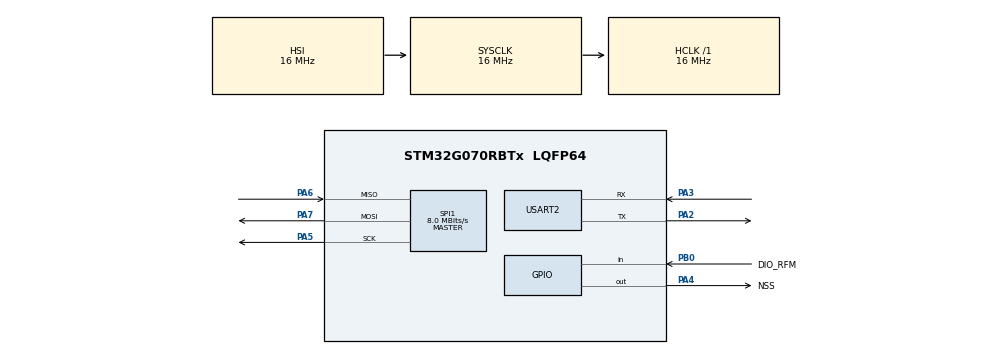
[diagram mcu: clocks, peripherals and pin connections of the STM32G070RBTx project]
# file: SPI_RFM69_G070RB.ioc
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Mcu.Family=STM32G0
Mcu.Name=STM32G070RBTx
Mcu.Package=LQFP64
PA13.GPIO_Label=TMS
PA13.Mode=Serial_Wire
PA13.Signal=SYS_SWDIO
PA14-BOOT0.GPIO_Label=TCK
PA14-BOOT0.Mode=Serial_Wire
PA14-BOOT0.Signal=SYS_SWCLK
PA2.GPIO_PuPd=GPIO_PULLUP
PA2.Mode=Asynchronous
PA2.Signal=USART2_TX
PA3.GPIO_PuPd=GPIO_PULLUP
PA3.Mode=Asynchronous
PA3.Signal=USART2_RX
PA4.GPIO_Label=NSS
PA4.Signal=GPIO_Output
PA5.Mode=Full_Duplex_Master
PA5.Signal=SPI1_SCK
PA6.Mode=Full_Duplex_Master
PA6.Signal=SPI1_MISO
PA7.Mode=Full_Duplex_Master
PA7.Signal=SPI1_MOSI
PB0.GPIO_Label=DIO_RFM
PB0.Signal=GPIO_Input
PC13.Mode=SYS_WakeUp1
PC13.Signal=SYS_WKUP2
PC14-OSC32_IN\ (PC14).Mode=LSE-External-Oscillator
PC14-OSC32_IN\ (PC14).Signal=RCC_OSC32_IN
PC15-OSC32_OUT\ (PC15).Mode=LSE-External-Oscillator
PC15-OSC32_OUT\ (PC15).Signal=RCC_OSC32_OUT
PF0-OSC_IN\ (PF0).GPIO_Label=MCO
PF0-OSC_IN\ (PF0).Mode=HSE-External-Clock-Source
PF0-OSC_IN\ (PF0).Signal=RCC_OSC_IN
ProjectManager.HeapSize=0x200
ProjectManager.StackSize=0x400
ProjectManager.TargetToolchain=Makefile
RCC.AHBFreq_Value=16000000
RCC.CortexFreq_Value=16000000
RCC.EXTERNAL_CLOCK_VALUE=12288000
RCC.HCLKFreq_Value=16000000
RCC.HSE_VALUE=8000000
RCC.HSI_VALUE=16000000
RCC.SYSCLKFreq_VALUE=16000000
RCC.VCOOutputFreq_Value=128000000
SPI1.CalculateBaudRate=8.0 MBits/s
SPI1.DataSize=SPI_DATASIZE_8BIT
SPI1.Direction=SPI_DIRECTION_2LINES
SPI1.Mode=SPI_MODE_MASTER
SPI1.VirtualType=VM_MASTER
USART2.VirtualMode-Asynchronous=VM_ASYNC
USART2.WordLength=WORDLENGTH_8B
board=NUCLEO-G070RB

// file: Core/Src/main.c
/* USER CODE BEGIN Header */
/**
  ******************************************************************************
  * @file           : main.c
  * @brief          : Main program body
  ******************************************************************************
  * @attention
  *
  * Copyright (c) 2024 STMicroelectronics.
  * All rights reserved.
  *
  * This software is licensed under terms that can be found in the LICENSE file
  * in the root directory of this software component.
  * If no LICENSE file comes with this software, it is provided AS-IS.
  *
  ******************************************************************************
  */
/* USER CODE END Header */
#include "main.h"

/* USER CODE BEGIN Includes */
#include "string.h"
/* USER CODE END Includes */

SPI_HandleTypeDef hspi1;

UART_HandleTypeDef huart2;

void SystemClock_Config(void);
static void MX_GPIO_Init(void);
static void MX_SPI1_Init(void);
static void MX_USART2_UART_Init(void);

int main(void)
{

  /* MCU Configuration--------------------------------------------------------*/

  /* Reset of all peripherals, Initializes the Flash interface and the Systick. */
  HAL_Init();

  /* Configure the system clock */
  SystemClock_Config();

  /* Initialize all configured peripherals */
  MX_GPIO_Init();
  MX_SPI1_Init();
  MX_USART2_UART_Init();

  /* Infinite loop */
  /* USER CODE BEGIN WHILE */
  char *message ="HelloWorld!\r\n";
  while (1)
  {
    HAL_GPIO_TogglePin(GPIOA,GPIO_PIN_5);
    HAL_Delay(100);

    if(HAL_GPIO_ReadPin(GPIOC,GPIO_PIN_13)==GPIO_PIN_RESET){

      HAL_UART_Transmit(&huart2, (uint8_t *)message, strlen(message),100);
    }
    /* USER CODE END WHILE */

  }
}

void SystemClock_Config(void)
{
  RCC_OscInitTypeDef RCC_OscInitStruct = {0};
  RCC_ClkInitTypeDef RCC_ClkInitStruct = {0};

  /** Configure the main internal regulator output voltage
  */
  HAL_PWREx_ControlVoltageScaling(PWR_REGULATOR_VOLTAGE_SCALE1);

  /** Initializes the RCC Oscillators according to the specified parameters
  * in the RCC_OscInitTypeDef structure.
  */
  RCC_OscInitStruct.OscillatorType = RCC_OSCILLATORTYPE_HSI;
  RCC_OscInitStruct.HSIState = RCC_HSI_ON;
  RCC_OscInitStruct.HSIDiv = RCC_HSI_DIV1;
  RCC_OscInitStruct.HSICalibrationValue = RCC_HSICALIBRATION_DEFAULT;
  RCC_OscInitStruct.PLL.PLLState = RCC_PLL_NONE;
  if (HAL_RCC_OscConfig(&RCC_OscInitStruct) != HAL_OK)
  {
    Error_Handler();
  }

  /** Initializes the CPU, AHB and APB buses clocks
  */
  RCC_ClkInitStruct.ClockType = RCC_CLOCKTYPE_HCLK|RCC_CLOCKTYPE_SYSCLK
                              |RCC_CLOCKTYPE_PCLK1;
  RCC_ClkInitStruct.SYSCLKSource = RCC_SYSCLKSOURCE_HSI;
  RCC_ClkInitStruct.AHBCLKDivider = RCC_SYSCLK_DIV1;
  RCC_ClkInitStruct.APB1CLKDivider = RCC_HCLK_DIV1;

  if (HAL_RCC_ClockConfig(&RCC_ClkInitStruct, FLASH_LATENCY_0) != HAL_OK)
  {
    Error_Handler();
  }
}

static void MX_SPI1_Init(void)
{

  /* SPI1 parameter configuration*/
  hspi1.Instance = SPI1;
  hspi1.Init.Mode = SPI_MODE_MASTER;
  hspi1.Init.Direction = SPI_DIRECTION_2LINES;
  hspi1.Init.DataSize = SPI_DATASIZE_8BIT;
  hspi1.Init.CLKPolarity = SPI_POLARITY_LOW;
  hspi1.Init.CLKPhase = SPI_PHASE_1EDGE;
  hspi1.Init.NSS = SPI_NSS_SOFT;
  hspi1.Init.BaudRatePrescaler = SPI_BAUDRATEPRESCALER_2;
  hspi1.Init.FirstBit = SPI_FIRSTBIT_MSB;
  hspi1.Init.TIMode = SPI_TIMODE_DISABLE;
  hspi1.Init.CRCCalculation = SPI_CRCCALCULATION_DISABLE;
  hspi1.Init.CRCPolynomial = 7;
  hspi1.Init.CRCLength = SPI_CRC_LENGTH_DATASIZE;
  hspi1.Init.NSSPMode = SPI_NSS_PULSE_ENABLE;
  if (HAL_SPI_Init(&hspi1) != HAL_OK)
  {
    Error_Handler();
  }

}

static void MX_USART2_UART_Init(void)
{

  huart2.Instance = USART2;
  huart2.Init.BaudRate = 115200;
  huart2.Init.WordLength = UART_WORDLENGTH_8B;
  huart2.Init.StopBits = UART_STOPBITS_1;
  huart2.Init.Parity = UART_PARITY_NONE;
  huart2.Init.Mode = UART_MODE_TX_RX;
  huart2.Init.HwFlowCtl = UART_HWCONTROL_NONE;
  huart2.Init.OverSampling = UART_OVERSAMPLING_16;
  huart2.Init.OneBitSampling = UART_ONE_BIT_SAMPLE_DISABLE;
  huart2.Init.ClockPrescaler = UART_PRESCALER_DIV1;
  huart2.AdvancedInit.AdvFeatureInit = UART_ADVFEATURE_NO_INIT;
  if (HAL_UART_Init(&huart2) != HAL_OK)
  {
    Error_Handler();
  }
  if (HAL_UARTEx_SetTxFifoThreshold(&huart2, UART_TXFIFO_THRESHOLD_1_8) != HAL_OK)
  {
    Error_Handler();
  }
  if (HAL_UARTEx_SetRxFifoThreshold(&huart2, UART_RXFIFO_THRESHOLD_1_8) != HAL_OK)
  {
    Error_Handler();
  }
  if (HAL_UARTEx_DisableFifoMode(&huart2) != HAL_OK)
  {
    Error_Handler();
  }

}

static void MX_GPIO_Init(void)
{
  GPIO_InitTypeDef GPIO_InitStruct = {0};

  /* GPIO Ports Clock Enable */
  __HAL_RCC_GPIOC_CLK_ENABLE();
  __HAL_RCC_GPIOF_CLK_ENABLE();
  __HAL_RCC_GPIOA_CLK_ENABLE();
  __HAL_RCC_GPIOB_CLK_ENABLE();

  /*Configure GPIO pin Output Level */
  HAL_GPIO_WritePin(NSS_GPIO_Port, NSS_Pin, GPIO_PIN_RESET);

  /*Configure GPIO pin : NSS_Pin */
  GPIO_InitStruct.Pin = NSS_Pin;
  GPIO_InitStruct.Mode = GPIO_MODE_OUTPUT_PP;
  GPIO_InitStruct.Pull = GPIO_NOPULL;
  GPIO_InitStruct.Speed = GPIO_SPEED_FREQ_LOW;
  HAL_GPIO_Init(NSS_GPIO_Port, &GPIO_InitStruct);

  /*Configure GPIO pin : DIO_RFM_Pin */
  GPIO_InitStruct.Pin = DIO_RFM_Pin;
  GPIO_InitStruct.Mode = GPIO_MODE_INPUT;
  GPIO_InitStruct.Pull = GPIO_NOPULL;
  HAL_GPIO_Init(DIO_RFM_GPIO_Port, &GPIO_InitStruct);

}

void Error_Handler(void)
{
  __disable_irq();
  while (1)
  {
  }
}
